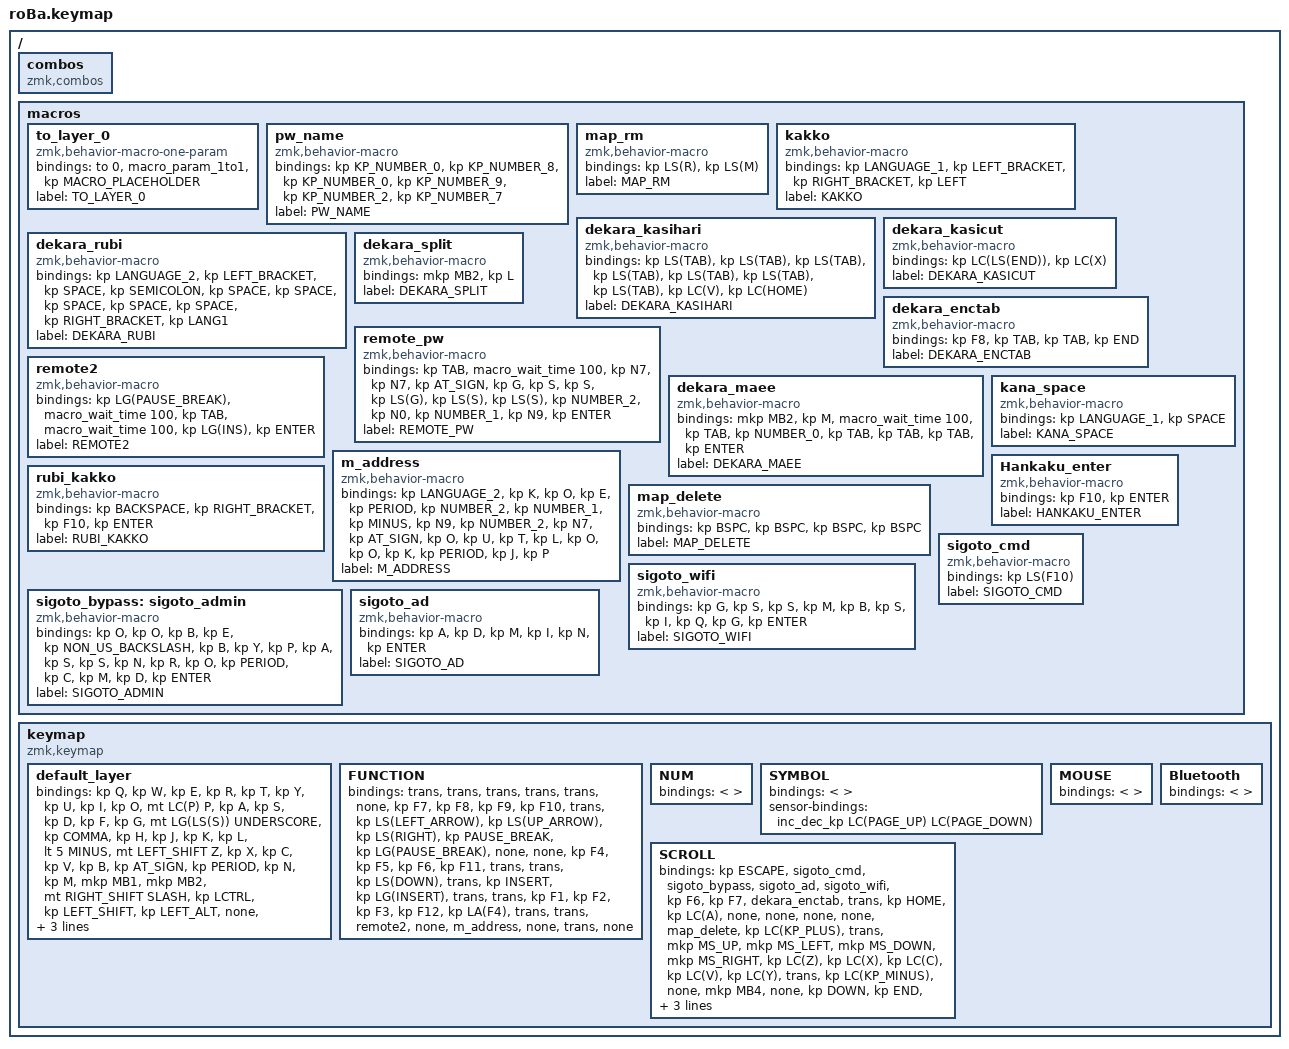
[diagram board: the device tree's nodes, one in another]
#include <behaviors.dtsi>
#include <dt-bindings/zmk/keys.h>
#include <dt-bindings/zmk/pointing.h>

#define MOUSE 4
#define SCROLL 5
#define NUM 6

/ {
    combos { compatible = "zmk,combos"; };

    macros {
        to_layer_0: to_layer_0 {
            compatible = "zmk,behavior-macro-one-param";
            #binding-cells = <1>;
            bindings = <&to 0 &macro_param_1to1 &kp MACRO_PLACEHOLDER>;
            label = "TO_LAYER_0";
        };

        pw_name: pw_name {
            compatible = "zmk,behavior-macro";
            #binding-cells = <0>;
            bindings = <&kp KP_NUMBER_0 &kp KP_NUMBER_8 &kp KP_NUMBER_0 &kp KP_NUMBER_9 &kp KP_NUMBER_2 &kp KP_NUMBER_7>;
            label = "PW_NAME";
        };

        map_rm: map_rm {
            compatible = "zmk,behavior-macro";
            #binding-cells = <0>;
            bindings = <&kp LS(R) &kp LS(M)>;
            label = "MAP_RM";
        };

        kakko: kakko {
            compatible = "zmk,behavior-macro";
            #binding-cells = <0>;
            bindings = <&kp LANGUAGE_1 &kp LEFT_BRACKET &kp RIGHT_BRACKET &kp LEFT>;
            label = "KAKKO";
        };

        dekara_kasihari: dekara_kasihari {
            compatible = "zmk,behavior-macro";
            #binding-cells = <0>;
            bindings = <&kp LS(TAB) &kp LS(TAB) &kp LS(TAB) &kp LS(TAB) &kp LS(TAB) &kp LS(TAB) &kp LS(TAB) &kp LC(V) &kp LC(HOME)>;
            label = "DEKARA_KASIHARI";
        };

        dekara_kasicut: dekara_kasicut {
            compatible = "zmk,behavior-macro";
            #binding-cells = <0>;
            bindings = <&kp LC(LS(END)) &kp LC(X)>;
            label = "DEKARA_KASICUT";
        };

        dekara_rubi: dekara_rubi {
            compatible = "zmk,behavior-macro";
            #binding-cells = <0>;
            bindings = <&kp LANGUAGE_2 &kp LEFT_BRACKET &kp SPACE &kp SEMICOLON &kp SPACE &kp SPACE &kp SPACE &kp SPACE &kp SPACE &kp RIGHT_BRACKET &kp LANG1>;
            label = "DEKARA_RUBI";
        };

        dekara_split: dekara_split {
            compatible = "zmk,behavior-macro";
            #binding-cells = <0>;
            bindings = <&mkp MB2 &kp L>;
            label = "DEKARA_SPLIT";
        };

        dekara_enctab: dekara_enctab {
            compatible = "zmk,behavior-macro";
            #binding-cells = <0>;
            bindings = <&kp F8 &kp TAB &kp TAB &kp END>;
            label = "DEKARA_ENCTAB";
        };

        remote_pw: remote_pw {
            compatible = "zmk,behavior-macro";
            #binding-cells = <0>;
            bindings =
                <&kp TAB>,
                <&macro_wait_time 100>,
                <&kp N7 &kp N7 &kp AT_SIGN &kp G &kp S &kp S &kp LS(G) &kp LS(S) &kp LS(S) &kp NUMBER_2 &kp N0 &kp NUMBER_1 &kp N9 &kp ENTER>;

            label = "REMOTE_PW";
        };

        remote2: remote2 {
            compatible = "zmk,behavior-macro";
            #binding-cells = <0>;
            bindings =
                <&kp LG(PAUSE_BREAK)>,
                <&macro_wait_time 100>,
                <&kp TAB>,
                <&macro_wait_time 100>,
                <&kp LG(INS) &kp ENTER>;

            label = "REMOTE2";
        };

        dekara_maee: dekara_maee {
            compatible = "zmk,behavior-macro";
            #binding-cells = <0>;
            bindings =
                <&mkp MB2 &kp M>,
                <&macro_wait_time 100>,
                <&kp TAB &kp NUMBER_0 &kp TAB &kp TAB &kp TAB &kp ENTER>;

            label = "DEKARA_MAEE";
        };

        m_address: m_address {
            compatible = "zmk,behavior-macro";
            #binding-cells = <0>;
            bindings = <&kp LANGUAGE_2 &kp K &kp O &kp E &kp PERIOD &kp NUMBER_2 &kp NUMBER_1 &kp MINUS &kp N9 &kp NUMBER_2 &kp N7 &kp AT_SIGN &kp O &kp U &kp T &kp L &kp O &kp O &kp K &kp PERIOD &kp J &kp P>;
            label = "M_ADDRESS";
        };

        kana_space: kana_space {
            compatible = "zmk,behavior-macro";
            #binding-cells = <0>;
            bindings = <&kp LANGUAGE_1 &kp SPACE>;
            label = "KANA_SPACE";
        };

        map_delete: map_delete {
            compatible = "zmk,behavior-macro";
            #binding-cells = <0>;
            bindings = <&kp BSPC &kp BSPC &kp BSPC &kp BSPC>;
            label = "MAP_DELETE";
        };

        Hankaku_enter: Hankaku_enter {
            compatible = "zmk,behavior-macro";
            #binding-cells = <0>;
            bindings = <&kp F10 &kp ENTER>;
            label = "HANKAKU_ENTER";
        };

        rubi_kakko: rubi_kakko {
            compatible = "zmk,behavior-macro";
            #binding-cells = <0>;
            bindings = <&kp BACKSPACE &kp RIGHT_BRACKET &kp F10 &kp ENTER>;
            label = "RUBI_KAKKO";
        };

        sigoto_cmd: sigoto_cmd {
            compatible = "zmk,behavior-macro";
            #binding-cells = <0>;
            bindings = <&kp LS(F10)>;
            label = "SIGOTO_CMD";
        };

        sigoto_bypass: sigoto_admin {
            compatible = "zmk,behavior-macro";
            #binding-cells = <0>;
            bindings = <&kp O &kp O &kp B &kp E &kp NON_US_BACKSLASH &kp B &kp Y &kp P &kp A &kp S &kp S &kp N &kp R &kp O &kp PERIOD &kp C &kp M &kp D &kp ENTER>;
            label = "SIGOTO_ADMIN";
        };

        sigoto_wifi: sigoto_wifi {
            compatible = "zmk,behavior-macro";
            #binding-cells = <0>;
            bindings = <&kp G &kp S &kp S &kp M &kp B &kp S &kp I &kp Q &kp G &kp ENTER>;
            label = "SIGOTO_WIFI";
        };

        sigoto_ad: sigoto_ad {
            compatible = "zmk,behavior-macro";
            #binding-cells = <0>;
            bindings = <&kp A &kp D &kp M &kp I &kp N &kp ENTER>;
            label = "SIGOTO_AD";
        };
    };

    keymap {
        compatible = "zmk,keymap";

        default_layer {
            bindings = <
&kp Q             &kp W           &kp E         &kp R  &kp T                                                          &kp Y        &kp U  &kp I     &kp O     &mt LC(P) P
&kp A             &kp S           &kp D         &kp F  &kp G            &mt LG(LS(S)) UNDERSCORE      &kp COMMA       &kp H        &kp J  &kp K     &kp L     &lt 5 MINUS
&mt LEFT_SHIFT Z  &kp X           &kp C         &kp V  &kp B            &kp AT_SIGN                   &kp PERIOD      &kp N        &kp M  &mkp MB1  &mkp MB2  &mt RIGHT_SHIFT SLASH
&kp LCTRL         &kp LEFT_SHIFT  &kp LEFT_ALT  &none  &lt 5 LS(SPACE)  &lt 3 TAB                     &lt 6 LEFT_GUI  &lt 1 ENTER                             &kp BACKSPACE
            >;

            sensor-bindings = <&inc_dec_kp PAGE_UP PAGE_DOWN>;
        };

        FUNCTION {
            bindings = <
&trans      &trans              &trans            &trans         &trans                                            &none   &kp F7  &kp F8  &kp F9  &kp F10
&trans      &kp LS(LEFT_ARROW)  &kp LS(UP_ARROW)  &kp LS(RIGHT)  &kp PAUSE_BREAK  &kp LG(PAUSE_BREAK)      &none   &none   &kp F4  &kp F5  &kp F6  &kp F11
&trans      &trans              &kp LS(DOWN)      &trans         &kp INSERT       &kp LG(INSERT)           &trans  &trans  &kp F1  &kp F2  &kp F3  &kp F12
&kp LA(F4)  &trans              &trans            &remote2       &none            &m_address               &none   &trans                          &none
            >;
        };

        NUM {
            bindings = <

            >;

            // 元の NUM レイヤーそのまま
        };

        SYMBOL {
            bindings = <

            >;

            // 元の SYMBOL レイヤーそのまま

            sensor-bindings = <&inc_dec_kp LC(PAGE_UP) LC(PAGE_DOWN)>;
        };

        MOUSE {
            bindings = <

            >;

            // 元の MOUSE レイヤーそのまま
        };

        SCROLL {
            bindings = <
&kp ESCAPE  &sigoto_cmd  &sigoto_bypass  &sigoto_ad  &sigoto_wifi                                     &kp F6                     &kp F7      &dekara_enctab  &trans        &kp HOME
&kp LC(A)   &none        &none           &none       &none         &map_delete      &kp LC(KP_PLUS)   &trans                     &mkp MS_UP  &mkp MS_LEFT    &mkp MS_DOWN  &mkp MS_RIGHT
&kp LC(Z)   &kp LC(X)    &kp LC(C)       &kp LC(V)   &kp LC(Y)     &trans           &kp LC(KP_MINUS)  &none                      &mkp MB4    &none           &kp DOWN      &kp END
&pw_name    &trans       &trans          &trans      &trans        &trans           &none             &mt LANGUAGE_2 LANGUAGE_1                                            &kp DEL
            >;

            sensor-bindings = <&inc_dec_kp PAGE_UP PAGE_DOWN>;
        };

        Bluetooth {
            bindings = <

            >;

            // 元の Bluetooth レイヤーそのまま
        };
    };
};
